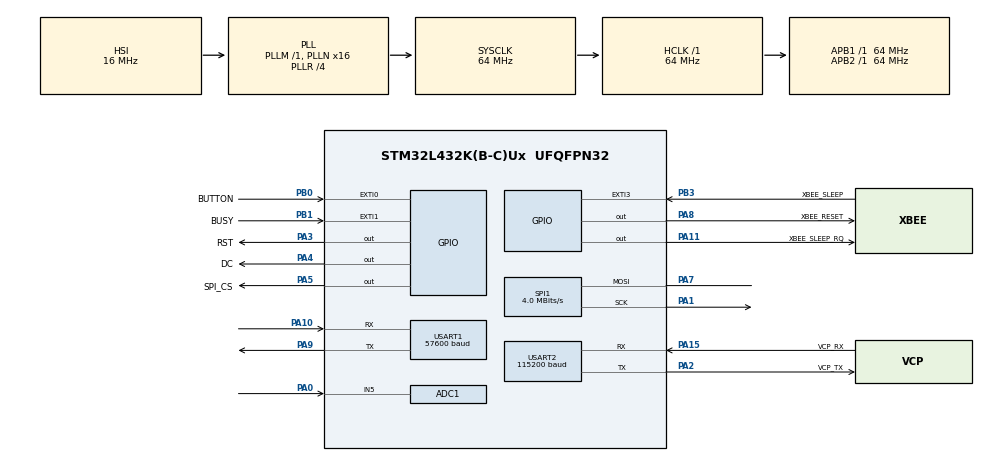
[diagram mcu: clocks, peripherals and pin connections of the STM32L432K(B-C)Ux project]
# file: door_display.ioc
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ADC1.Channel-0\#ChannelRegularConversion=ADC_CHANNEL_5
ADC1.NbrOfConversionFlag=1
ADC1.OffsetNumber-0\#ChannelRegularConversion=ADC_OFFSET_NONE
ADC1.Rank-0\#ChannelRegularConversion=1
ADC1.SamplingTime-0\#ChannelRegularConversion=ADC_SAMPLETIME_2CYCLES_5
ADC1.master=1
Dma.Request0=SPI1_TX
Dma.SPI1_TX.0.Direction=DMA_MEMORY_TO_PERIPH
Dma.SPI1_TX.0.Instance=DMA1_Channel3
Dma.SPI1_TX.0.MemDataAlignment=DMA_MDATAALIGN_BYTE
Dma.SPI1_TX.0.MemInc=DMA_MINC_DISABLE
Dma.SPI1_TX.0.Mode=DMA_NORMAL
Dma.SPI1_TX.0.PeriphDataAlignment=DMA_PDATAALIGN_BYTE
Dma.SPI1_TX.0.PeriphInc=DMA_PINC_DISABLE
Dma.SPI1_TX.0.Priority=DMA_PRIORITY_VERY_HIGH
Mcu.Family=STM32L4
Mcu.Name=STM32L432K(B-C)Ux
Mcu.Package=UFQFPN32
NVIC.DMA1_Channel3_IRQn=true\:0\:0\:false\:false\:true\:false\:true
NVIC.PriorityGroup=NVIC_PRIORITYGROUP_4
PA0.Signal=ADCx_IN5
PA1.Mode=Simplex_Bidirectional_Master
PA1.Signal=SPI1_SCK
PA10.Mode=Asynchronous
PA10.Signal=USART1_RX
PA11.GPIO_Label=XBEE_SLEEP_RQ
PA11.Signal=GPIO_Output
PA13\ (JTMS-SWDIO).GPIO_Label=SWDIO
PA13\ (JTMS-SWDIO).Mode=Serial_Wire
PA13\ (JTMS-SWDIO).Signal=SYS_JTMS-SWDIO
PA14\ (JTCK-SWCLK).GPIO_Label=SWCLK
PA14\ (JTCK-SWCLK).Mode=Serial_Wire
PA14\ (JTCK-SWCLK).Signal=SYS_JTCK-SWCLK
PA15\ (JTDI).GPIO_Label=VCP_RX
PA15\ (JTDI).Mode=Asynchronous
PA15\ (JTDI).Signal=USART2_RX
PA2.GPIO_Label=VCP_TX
PA2.Mode=Asynchronous
PA2.Signal=USART2_TX
PA3.GPIO_Label=RST
PA3.Signal=GPIO_Output
PA4.GPIO_Label=DC
PA4.Signal=GPIO_Output
PA5.GPIO_Label=SPI_CS
PA5.PinState=GPIO_PIN_SET
PA5.Signal=GPIO_Output
PA7.Mode=Simplex_Bidirectional_Master
PA7.Signal=SPI1_MOSI
PA8.GPIO_Label=XBEE_RESET
PA8.Signal=GPIO_Output
PA9.Mode=Asynchronous
PA9.Signal=USART1_TX
PB0.GPIO_Label=BUTTON
PB0.Signal=GPXTI0
PB1.GPIO_Label=BUSY
PB1.Signal=GPXTI1
PB3\ (JTDO-TRACESWO).GPIO_Label=XBEE_SLEEP
PB3\ (JTDO-TRACESWO).Signal=GPXTI3
PC14-OSC32_IN\ (PC14).Mode=LSE-External-Oscillator
PC14-OSC32_IN\ (PC14).Signal=RCC_OSC32_IN
PC15-OSC32_OUT\ (PC15).Mode=LSE-External-Oscillator
PC15-OSC32_OUT\ (PC15).Signal=RCC_OSC32_OUT
ProjectManager.HeapSize=0x200
ProjectManager.StackSize=0x400
ProjectManager.TargetToolchain=STM32CubeIDE
RCC.ADCCLockSelection=RCC_ADCCLKSOURCE_SYSCLK
RCC.ADCFreq_Value=64000000
RCC.AHBFreq_Value=64000000
RCC.APB1Freq_Value=64000000
RCC.APB1TimFreq_Value=64000000
RCC.APB2Freq_Value=64000000
RCC.APB2TimFreq_Value=64000000
RCC.CortexFreq_Value=8000000
RCC.Cortex_Div=SYSTICK_CLKSOURCE_HCLK_DIV8
RCC.HCLKFreq_Value=64000000
RCC.HSE_VALUE=8000000
RCC.HSI16_VALUE=16000000
RCC.HSI48_VALUE=48000000
RCC.HSI_VALUE=16000000
RCC.MSI_VALUE=4000000
RCC.PLLMUL=RCC_PLLMUL_4
RCC.PLLN=16
RCC.PLLR=RCC_PLLR_DIV4
RCC.PLLSAI1N=16
RCC.PLLSAI1R=RCC_PLLR_DIV8
RCC.PLLSourceVirtual=RCC_PLLSOURCE_HSI
RCC.RTCClockSelection=RCC_RTCCLKSOURCE_LSE
RCC.SYSCLKFreq_VALUE=64000000
RCC.SYSCLKSource=RCC_SYSCLKSOURCE_PLLCLK
RCC.USART1CLockSelection=RCC_USART1CLKSOURCE_HSI
RCC.USART2CLockSelection=RCC_USART2CLKSOURCE_HSI
RCC.USBFreq_Value=128000000
RCC.VCOOutputFreq_Value=256000000
RTC.Alarm=RTC_ALARM_A
SH.ADCx_IN5.0=ADC1_IN5,IN5-Single-Ended
SPI1.BaudRatePrescaler=SPI_BAUDRATEPRESCALER_16
SPI1.CalculateBaudRate=4.0 MBits/s
SPI1.DataSize=SPI_DATASIZE_8BIT
SPI1.Direction=SPI_DIRECTION_1LINE
SPI1.Mode=SPI_MODE_MASTER
SPI1.NSSPMode=SPI_NSS_PULSE_DISABLE
SPI1.VirtualType=VM_MASTER
USART1.BaudRate=57600
USART1.VirtualMode-Asynchronous=VM_ASYNC
USART2.BaudRate=115200
USART2.VirtualMode-Asynchronous=VM_ASYNC
VP_RTC_VS_RTC_Activate.Mode=RTC_Enabled
VP_RTC_VS_RTC_Alarm_A_Intern.Mode=Alarm A
VP_RTC_VS_RTC_Calendar.Mode=RTC_Calendar
board=NUCLEO-L432KC

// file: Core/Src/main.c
/* USER CODE BEGIN Header */
/**
  ******************************************************************************
  * @file           : main.c
  * @brief          : Main program body
  ******************************************************************************
  * @attention
  *
  * <h2><center>&copy; Copyright (c) 2021 STMicroelectronics.
  * All rights reserved.</center></h2>
  *
  * This software component is licensed by ST under BSD 3-Clause license,
  * the "License"; You may not use this file except in compliance with the
  * License. You may obtain a copy of the License at:
  *                        opensource.org/licenses/BSD-3-Clause
  *
  ******************************************************************************
  */
/* USER CODE END Header */
#include "main.h"

/* USER CODE BEGIN Includes */
#include "EPD_Test.h"
/* USER CODE END Includes */

ADC_HandleTypeDef hadc1;

RTC_HandleTypeDef hrtc;

SPI_HandleTypeDef hspi1;
DMA_HandleTypeDef hdma_spi1_tx;

UART_HandleTypeDef huart1;
UART_HandleTypeDef huart2;

void SystemClock_Config(void);
static void MX_GPIO_Init(void);
static void MX_USART2_UART_Init(void);
static void MX_ADC1_Init(void);
static void MX_RTC_Init(void);
static void MX_SPI1_Init(void);
static void MX_DMA_Init(void);
static void MX_USART1_UART_Init(void);

int main(void)
{

  /* MCU Configuration--------------------------------------------------------*/

  /* Reset of all peripherals, Initializes the Flash interface and the Systick. */
  HAL_Init();

  /* Configure the system clock */
  SystemClock_Config();

  /* Initialize all configured peripherals */
  MX_GPIO_Init();
  MX_USART2_UART_Init();
  MX_ADC1_Init();
  MX_RTC_Init();
  MX_SPI1_Init();
  MX_DMA_Init();
  MX_USART1_UART_Init();
  /* USER CODE BEGIN 2 */
  EPD_7in5_V2_test();
  //EPD_7in5b_V2_test();
  //EPD_7in5_test();
  //EPD_7in5_HD_test();
  /* USER CODE END 2 */

  /* Infinite loop */
  while (1)
  {

  }
}

void SystemClock_Config(void)
{
  RCC_OscInitTypeDef RCC_OscInitStruct = {0};
  RCC_ClkInitTypeDef RCC_ClkInitStruct = {0};

  /** Configure the main internal regulator output voltage
  */
  if (HAL_PWREx_ControlVoltageScaling(PWR_REGULATOR_VOLTAGE_SCALE1) != HAL_OK)
  {
    Error_Handler();
  }
  /** Configure LSE Drive Capability
  */
  HAL_PWR_EnableBkUpAccess();
  __HAL_RCC_LSEDRIVE_CONFIG(RCC_LSEDRIVE_LOW);
  /** Initializes the RCC Oscillators according to the specified parameters
  * in the RCC_OscInitTypeDef structure.
  */
  RCC_OscInitStruct.OscillatorType = RCC_OSCILLATORTYPE_HSI|RCC_OSCILLATORTYPE_LSE;
  RCC_OscInitStruct.LSEState = RCC_LSE_ON;
  RCC_OscInitStruct.HSIState = RCC_HSI_ON;
  RCC_OscInitStruct.HSICalibrationValue = RCC_HSICALIBRATION_DEFAULT;
  RCC_OscInitStruct.PLL.PLLState = RCC_PLL_ON;
  RCC_OscInitStruct.PLL.PLLSource = RCC_PLLSOURCE_HSI;
  RCC_OscInitStruct.PLL.PLLM = 1;
  RCC_OscInitStruct.PLL.PLLN = 16;
  RCC_OscInitStruct.PLL.PLLP = RCC_PLLP_DIV7;
  RCC_OscInitStruct.PLL.PLLQ = RCC_PLLQ_DIV2;
  RCC_OscInitStruct.PLL.PLLR = RCC_PLLR_DIV4;
  if (HAL_RCC_OscConfig(&RCC_OscInitStruct) != HAL_OK)
  {
    Error_Handler();
  }
  /** Initializes the CPU, AHB and APB buses clocks
  */
  RCC_ClkInitStruct.ClockType = RCC_CLOCKTYPE_HCLK|RCC_CLOCKTYPE_SYSCLK
                              |RCC_CLOCKTYPE_PCLK1|RCC_CLOCKTYPE_PCLK2;
  RCC_ClkInitStruct.SYSCLKSource = RCC_SYSCLKSOURCE_PLLCLK;
  RCC_ClkInitStruct.AHBCLKDivider = RCC_SYSCLK_DIV1;
  RCC_ClkInitStruct.APB1CLKDivider = RCC_HCLK_DIV1;
  RCC_ClkInitStruct.APB2CLKDivider = RCC_HCLK_DIV1;

  if (HAL_RCC_ClockConfig(&RCC_ClkInitStruct, FLASH_LATENCY_3) != HAL_OK)
  {
    Error_Handler();
  }
}

static void MX_ADC1_Init(void)
{

  ADC_ChannelConfTypeDef sConfig = {0};

  /** Common config
  */
  hadc1.Instance = ADC1;
  hadc1.Init.ClockPrescaler = ADC_CLOCK_ASYNC_DIV1;
  hadc1.Init.Resolution = ADC_RESOLUTION_12B;
  hadc1.Init.DataAlign = ADC_DATAALIGN_RIGHT;
  hadc1.Init.ScanConvMode = ADC_SCAN_DISABLE;
  hadc1.Init.EOCSelection = ADC_EOC_SINGLE_CONV;
  hadc1.Init.LowPowerAutoWait = DISABLE;
  hadc1.Init.ContinuousConvMode = DISABLE;
  hadc1.Init.NbrOfConversion = 1;
  hadc1.Init.DiscontinuousConvMode = DISABLE;
  hadc1.Init.ExternalTrigConv = ADC_SOFTWARE_START;
  hadc1.Init.ExternalTrigConvEdge = ADC_EXTERNALTRIGCONVEDGE_NONE;
  hadc1.Init.DMAContinuousRequests = DISABLE;
  hadc1.Init.Overrun = ADC_OVR_DATA_PRESERVED;
  hadc1.Init.OversamplingMode = DISABLE;
  if (HAL_ADC_Init(&hadc1) != HAL_OK)
  {
    Error_Handler();
  }
  /** Configure Regular Channel
  */
  sConfig.Channel = ADC_CHANNEL_5;
  sConfig.Rank = ADC_REGULAR_RANK_1;
  sConfig.SamplingTime = ADC_SAMPLETIME_2CYCLES_5;
  sConfig.SingleDiff = ADC_SINGLE_ENDED;
  sConfig.OffsetNumber = ADC_OFFSET_NONE;
  sConfig.Offset = 0;
  if (HAL_ADC_ConfigChannel(&hadc1, &sConfig) != HAL_OK)
  {
    Error_Handler();
  }

}

static void MX_RTC_Init(void)
{

  RTC_TimeTypeDef sTime = {0};
  RTC_DateTypeDef sDate = {0};
  RTC_AlarmTypeDef sAlarm = {0};

  /** Initialize RTC Only
  */
  hrtc.Instance = RTC;
  hrtc.Init.HourFormat = RTC_HOURFORMAT_24;
  hrtc.Init.AsynchPrediv = 127;
  hrtc.Init.SynchPrediv = 255;
  hrtc.Init.OutPut = RTC_OUTPUT_DISABLE;
  hrtc.Init.OutPutRemap = RTC_OUTPUT_REMAP_NONE;
  hrtc.Init.OutPutPolarity = RTC_OUTPUT_POLARITY_HIGH;
  hrtc.Init.OutPutType = RTC_OUTPUT_TYPE_OPENDRAIN;
  if (HAL_RTC_Init(&hrtc) != HAL_OK)
  {
    Error_Handler();
  }

  /** Initialize RTC and set the Time and Date
  */
  sTime.Hours = 0x0;
  sTime.Minutes = 0x0;
  sTime.Seconds = 0x0;
  sTime.DayLightSaving = RTC_DAYLIGHTSAVING_NONE;
  sTime.StoreOperation = RTC_STOREOPERATION_RESET;
  if (HAL_RTC_SetTime(&hrtc, &sTime, RTC_FORMAT_BCD) != HAL_OK)
  {
    Error_Handler();
  }
  sDate.WeekDay = RTC_WEEKDAY_MONDAY;
  sDate.Month = RTC_MONTH_JANUARY;
  sDate.Date = 0x1;
  sDate.Year = 0x0;

  if (HAL_RTC_SetDate(&hrtc, &sDate, RTC_FORMAT_BCD) != HAL_OK)
  {
    Error_Handler();
  }
  /** Enable the Alarm A
  */
  sAlarm.AlarmTime.Hours = 0x0;
  sAlarm.AlarmTime.Minutes = 0x0;
  sAlarm.AlarmTime.Seconds = 0x0;
  sAlarm.AlarmTime.SubSeconds = 0x0;
  sAlarm.AlarmTime.DayLightSaving = RTC_DAYLIGHTSAVING_NONE;
  sAlarm.AlarmTime.StoreOperation = RTC_STOREOPERATION_RESET;
  sAlarm.AlarmMask = RTC_ALARMMASK_NONE;
  sAlarm.AlarmSubSecondMask = RTC_ALARMSUBSECONDMASK_ALL;
  sAlarm.AlarmDateWeekDaySel = RTC_ALARMDATEWEEKDAYSEL_DATE;
  sAlarm.AlarmDateWeekDay = 0x1;
  sAlarm.Alarm = RTC_ALARM_A;
  if (HAL_RTC_SetAlarm(&hrtc, &sAlarm, RTC_FORMAT_BCD) != HAL_OK)
  {
    Error_Handler();
  }

}

static void MX_SPI1_Init(void)
{

  /* SPI1 parameter configuration*/
  hspi1.Instance = SPI1;
  hspi1.Init.Mode = SPI_MODE_MASTER;
  hspi1.Init.Direction = SPI_DIRECTION_1LINE;
  hspi1.Init.DataSize = SPI_DATASIZE_8BIT;
  hspi1.Init.CLKPolarity = SPI_POLARITY_LOW;
  hspi1.Init.CLKPhase = SPI_PHASE_1EDGE;
  hspi1.Init.NSS = SPI_NSS_SOFT;
  hspi1.Init.BaudRatePrescaler = SPI_BAUDRATEPRESCALER_16;
  hspi1.Init.FirstBit = SPI_FIRSTBIT_MSB;
  hspi1.Init.TIMode = SPI_TIMODE_DISABLE;
  hspi1.Init.CRCCalculation = SPI_CRCCALCULATION_DISABLE;
  hspi1.Init.CRCPolynomial = 7;
  hspi1.Init.CRCLength = SPI_CRC_LENGTH_DATASIZE;
  hspi1.Init.NSSPMode = SPI_NSS_PULSE_DISABLE;
  if (HAL_SPI_Init(&hspi1) != HAL_OK)
  {
    Error_Handler();
  }

}

static void MX_USART1_UART_Init(void)
{

  huart1.Instance = USART1;
  huart1.Init.BaudRate = 57600;
  huart1.Init.WordLength = UART_WORDLENGTH_8B;
  huart1.Init.StopBits = UART_STOPBITS_1;
  huart1.Init.Parity = UART_PARITY_NONE;
  huart1.Init.Mode = UART_MODE_TX_RX;
  huart1.Init.HwFlowCtl = UART_HWCONTROL_NONE;
  huart1.Init.OverSampling = UART_OVERSAMPLING_16;
  huart1.Init.OneBitSampling = UART_ONE_BIT_SAMPLE_DISABLE;
  huart1.AdvancedInit.AdvFeatureInit = UART_ADVFEATURE_NO_INIT;
  if (HAL_UART_Init(&huart1) != HAL_OK)
  {
    Error_Handler();
  }

}

static void MX_USART2_UART_Init(void)
{

  huart2.Instance = USART2;
  huart2.Init.BaudRate = 115200;
  huart2.Init.WordLength = UART_WORDLENGTH_8B;
  huart2.Init.StopBits = UART_STOPBITS_1;
  huart2.Init.Parity = UART_PARITY_NONE;
  huart2.Init.Mode = UART_MODE_TX_RX;
  huart2.Init.HwFlowCtl = UART_HWCONTROL_NONE;
  huart2.Init.OverSampling = UART_OVERSAMPLING_16;
  huart2.Init.OneBitSampling = UART_ONE_BIT_SAMPLE_DISABLE;
  huart2.AdvancedInit.AdvFeatureInit = UART_ADVFEATURE_NO_INIT;
  if (HAL_UART_Init(&huart2) != HAL_OK)
  {
    Error_Handler();
  }

}

static void MX_DMA_Init(void)
{

  /* DMA controller clock enable */
  __HAL_RCC_DMA1_CLK_ENABLE();

  /* DMA interrupt init */
  /* DMA1_Channel3_IRQn interrupt configuration */
  HAL_NVIC_SetPriority(DMA1_Channel3_IRQn, 0, 0);
  HAL_NVIC_EnableIRQ(DMA1_Channel3_IRQn);

}

static void MX_GPIO_Init(void)
{
  GPIO_InitTypeDef GPIO_InitStruct = {0};

  /* GPIO Ports Clock Enable */
  __HAL_RCC_GPIOC_CLK_ENABLE();
  __HAL_RCC_GPIOA_CLK_ENABLE();
  __HAL_RCC_GPIOB_CLK_ENABLE();

  /*Configure GPIO pin Output Level */
  HAL_GPIO_WritePin(GPIOA, RST_Pin|DC_Pin|XBEE_RESET_Pin|XBEE_SLEEP_RQ_Pin, GPIO_PIN_RESET);

  /*Configure GPIO pin Output Level */
  HAL_GPIO_WritePin(SPI_CS_GPIO_Port, SPI_CS_Pin, GPIO_PIN_SET);

  /*Configure GPIO pins : RST_Pin DC_Pin SPI_CS_Pin XBEE_RESET_Pin
                           XBEE_SLEEP_RQ_Pin */
  GPIO_InitStruct.Pin = RST_Pin|DC_Pin|SPI_CS_Pin|XBEE_RESET_Pin
                          |XBEE_SLEEP_RQ_Pin;
  GPIO_InitStruct.Mode = GPIO_MODE_OUTPUT_PP;
  GPIO_InitStruct.Pull = GPIO_NOPULL;
  GPIO_InitStruct.Speed = GPIO_SPEED_FREQ_LOW;
  HAL_GPIO_Init(GPIOA, &GPIO_InitStruct);

  /*Configure GPIO pins : BUTTON_Pin BUSY_Pin XBEE_SLEEP_Pin */
  GPIO_InitStruct.Pin = BUTTON_Pin|BUSY_Pin|XBEE_SLEEP_Pin;
  GPIO_InitStruct.Mode = GPIO_MODE_IT_RISING;
  GPIO_InitStruct.Pull = GPIO_NOPULL;
  HAL_GPIO_Init(GPIOB, &GPIO_InitStruct);

}

/* USER CODE BEGIN 4 */
int __io_putchar(int ch)
{
	HAL_UART_Transmit(&huart2, (uint8_t*)&ch, 1, 500);

	return 1;
}

/* USER CODE END 4 */

void Error_Handler(void)
{
  __disable_irq();
  while (1)
  {
  }
}

/************************ (C) COPYRIGHT STMicroelectronics *****END OF FILE****/
